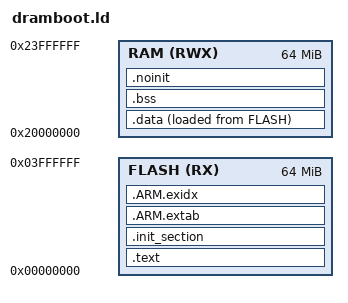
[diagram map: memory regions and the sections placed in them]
/****************************************************************************
 * boards/arm/fvp-v8r-aarch32/fvp-armv8r-aarch32/scripts/dramboot.ld
 *
 * Licensed to the Apache Software Foundation (ASF) under one or more
 * contributor license agreements.  See the NOTICE file distributed with
 * this work for additional information regarding copyright ownership.  The
 * ASF licenses this file to you under the Apache License, Version 2.0 (the
 * "License"); you may not use this file except in compliance with the
 * License.  You may obtain a copy of the License at
 *
 *   http://www.apache.org/licenses/LICENSE-2.0
 *
 * Unless required by applicable law or agreed to in writing, software
 * distributed under the License is distributed on an "AS IS" BASIS, WITHOUT
 * WARRANTIES OR CONDITIONS OF ANY KIND, either express or implied.  See the
 * License for the specific language governing permissions and limitations
 * under the License.
 *
 ****************************************************************************/

OUTPUT_ARCH(arm)

MEMORY
{
    FLASH (RX): ORIGIN = 0x00000000, LENGTH = 64M
    RAM  (RWX): ORIGIN = 0x20000000, LENGTH = 64M
}

ENTRY(__start)

SECTIONS
{
    .text :
    {
        _stext = ABSOLUTE(.);
        KEEP(*(.hyp_vectors))
        . = ALIGN(32);
        KEEP(*(.sys_vectors))
        *(.text .text.*)
        *(.fixup)
        *(.gnu.warning)
        *(.rodata .rodata.*)
        *(.gnu.linkonce.t.*)
        *(.glue_7)
        *(.glue_7t)
        *(.got)
        *(.gcc_except_table)
        *(.gnu.linkonce.r.*)
        *(.ARM.extab*)
        *(.gnu.linkonce.armextab.*)
        _etext = ABSOLUTE(.);
    } > FLASH

    .init_section :
    {
        _sinit = ABSOLUTE(.);
        *(.init_array .init_array.*)
        _einit = ABSOLUTE(.);
    } > FLASH

    .ARM.extab :
    {
        *(.ARM.extab*)
    } > FLASH

    /* .ARM.exidx is sorted, so has to go in its own output section.  */

    PROVIDE_HIDDEN (__exidx_start = .);
    .ARM.exidx :
    {
        *(.ARM.exidx* .gnu.linkonce.armexidx.*)
    } > FLASH
    PROVIDE_HIDDEN (__exidx_end = .);

    _eronly = ABSOLUTE(.);

    .data :
    {
        _sdata = ABSOLUTE(.);
        *(.data .data.*)
        *(.gnu.linkonce.d.*)
        CONSTRUCTORS
        . = ALIGN(4);
        _edata = ABSOLUTE(.);
    } > RAM AT > FLASH

    .bss :
    {
        _sbss = ABSOLUTE(.);
        *(.bss .bss.*)
        *(.gnu.linkonce.b.*)
        *(COMMON)
        . = ALIGN(4);
        _ebss = ABSOLUTE(.);
    } > RAM

    /* Uninitialized data */

    .noinit :
    {
        _snoinit = ABSOLUTE(.);
        *(.noinit*)
        _enoinit = ABSOLUTE(.);
    } > RAM

    /* Stabs debugging sections. */

    .stab 0 : { *(.stab) }
    .stabstr 0 : { *(.stabstr) }
    .stab.excl 0 : { *(.stab.excl) }
    .stab.exclstr 0 : { *(.stab.exclstr) }
    .stab.index 0 : { *(.stab.index) }
    .stab.indexstr 0 : { *(.stab.indexstr) }
    .comment 0 : { *(.comment) }
}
